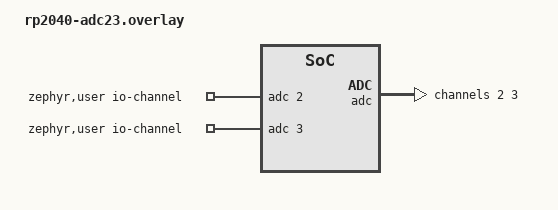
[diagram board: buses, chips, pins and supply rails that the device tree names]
/*
 * Copyright (c) 2024 TiaC Systems
 * SPDX-License-Identifier: Apache-2.0
 */

/ {
	zephyr,user {
		io-channels = <&adc 2>, <&adc 3>;
	};
};

&adc {
	#address-cells = <1>;
	#size-cells = <0>;

	channel@2 {
		reg = <2>;
		zephyr,gain = "ADC_GAIN_1";
		zephyr,reference = "ADC_REF_INTERNAL";
		zephyr,acquisition-time = <ADC_ACQ_TIME_DEFAULT>;
		zephyr,resolution = <12>;
	};

	channel@3 {
		reg = <3>;
		zephyr,gain = "ADC_GAIN_1";
		zephyr,reference = "ADC_REF_INTERNAL";
		zephyr,acquisition-time = <ADC_ACQ_TIME_DEFAULT>;
		zephyr,resolution = <12>;
	};
};
